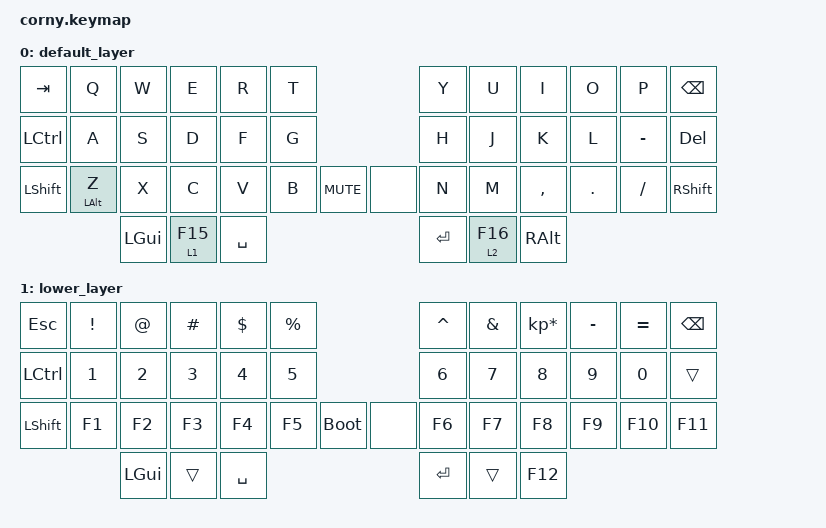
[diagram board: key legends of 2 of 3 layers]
#include <behaviors.dtsi>
#include <dt-bindings/zmk/keys.h>
#include <dt-bindings/zmk/bt.h>

&lt {
    tapping-term-ms = <200>;
};

/ {
        keymap {
                compatible = "zmk,keymap";

                default_layer {
// -------------------------------------------------------------------------------------------------
// |  TAB |  Q  |  W  |  E  |  R  |  T  |                    |  Y  |  U   |  I  |  O  |  P  | BKSP |
// | CTRL |  A  |  S  |  D  |  F  |  G  |                    |  H  |  J   |  K  |  L  |  ;  |  '   |
// | SHFT |  Z  |  X  |  C  |  V  |  B  |  MUTE  |  |        |  N  |  M   |  ,  |  .  |  /  | ESC  |
//                    | GUI | LWR | SPC |                    | ENT | RSE  | ALT |
                        bindings = <
   &kp TAB   &kp Q      &kp W &kp E &kp R &kp T                   &kp Y &kp U  &kp I     &kp O   &kp P     &kp BSPC
   &kp LCTRL &kp A      &kp S &kp D &kp F &kp G                   &kp H &kp J  &kp K     &kp L   &kp MINUS &kp DEL
   &kp LSHFT &mt LALT Z &kp X &kp C &kp V &kp B &kp C_MUTE  &none &kp N &kp M  &kp COMMA &kp DOT &kp FSLH  &kp RSHIFT
                        &kp LGUI &lt 1 F15 &kp SPACE              &kp RET &lt 2 F16 &kp RALT
                        >;

                        sensor-bindings = <&inc_dec_kp C_VOL_DN C_VOL_UP &inc_dec_kp PG_UP PG_DN>;
                };
                lower_layer {                
// ------------------------------------------------------------------------------------------------
// |  TAB |  !  |  @  |  #  |  $  |  %  |                    |  ^  |  &  |  *  |  (  |  )  | BKSP |
// |  CTL |  1  |  2  |  3  |  4  |  5  |                    |  6  |  7  |  8  |  9  |  0  |      |
// | SHFT | F1  | F2  | F3  | F4  | F5  |  boot  |  |        |  F6 | F7  | F8  | F9  | F10 |  F11 |
//                    | GUI |     | SPC |                    | ENT |     | F12 |
                        bindings = <
   &kp  ESC  &kp EXCL &kp AT &kp HASH &kp DLLR &kp PRCNT                   &kp CARET &kp AMPS &kp KP_MULTIPLY &kp MINUS &kp EQUAL &kp BSPC
   &kp LCTRL &kp N1   &kp N2 &kp N3   &kp N4   &kp N5                      &kp N6    &kp N7   &kp N8          &kp N9   &kp N0   &trans
   &kp LSHFT &kp F1   &kp F2 &kp F3   &kp F4   &kp F5    &bootloader &none &kp F6    &kp F7   &kp F8          &kp F9   &kp F10  &kp F11
                             &kp LGUI &trans   &kp SPACE                   &kp RET  &trans   &kp F12
                        >;

                        sensor-bindings = <&inc_dec_kp C_VOL_DN C_VOL_UP &inc_dec_kp PG_UP PG_DN>;
                };

                raise_layer {
// ------------------------------------------------------------------------------------------------
// |  TAB |  !  |  @  |  #  |  $  |  %  |                    |  ^  |  &  |  *  |  (  |  )  | BKSP |
// | SHFT |     |     |     |     |     |                    |  -  |  =  |  [  |  ]  |  \  |  `   |
// | BTCLR| BT1 | BT2 | BT3 | BT4 | BT5 |        |  |  boot  |  _  |  +  |  {  |  }  | "|" |  ~   |
//                    | GUI |     | SPC |                    | ENT |     | ALT |
                        bindings = <
   &kp GRAVE  &trans       &trans       &kp UP       &trans       &trans                    &trans &kp LBKT  &kp RBKT &kp MINUS &kp EQUAL &kp BSPC
   &trans     &trans       &kp LEFT     &kp DOWN     &kp RIGHT    &trans                    &trans &kp LBRC &kp RBRC  &kp SEMI &kp SQT  &kp BSLH
   &bt BT_CLR &bt BT_SEL 0 &bt BT_SEL 1 &bt BT_SEL 2 &bt BT_SEL 3 &bt BT_SEL 4  &bootloader &trans &trans &kp LPAR  &kp RPAR &trans   &trans
                           &trans       &trans       &kp SPACE                    &trans   &trans    &trans
                        >;

                        sensor-bindings = <&inc_dec_kp C_VOL_DN C_VOL_UP &inc_dec_kp PG_UP PG_DN>;
                };
        };
};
